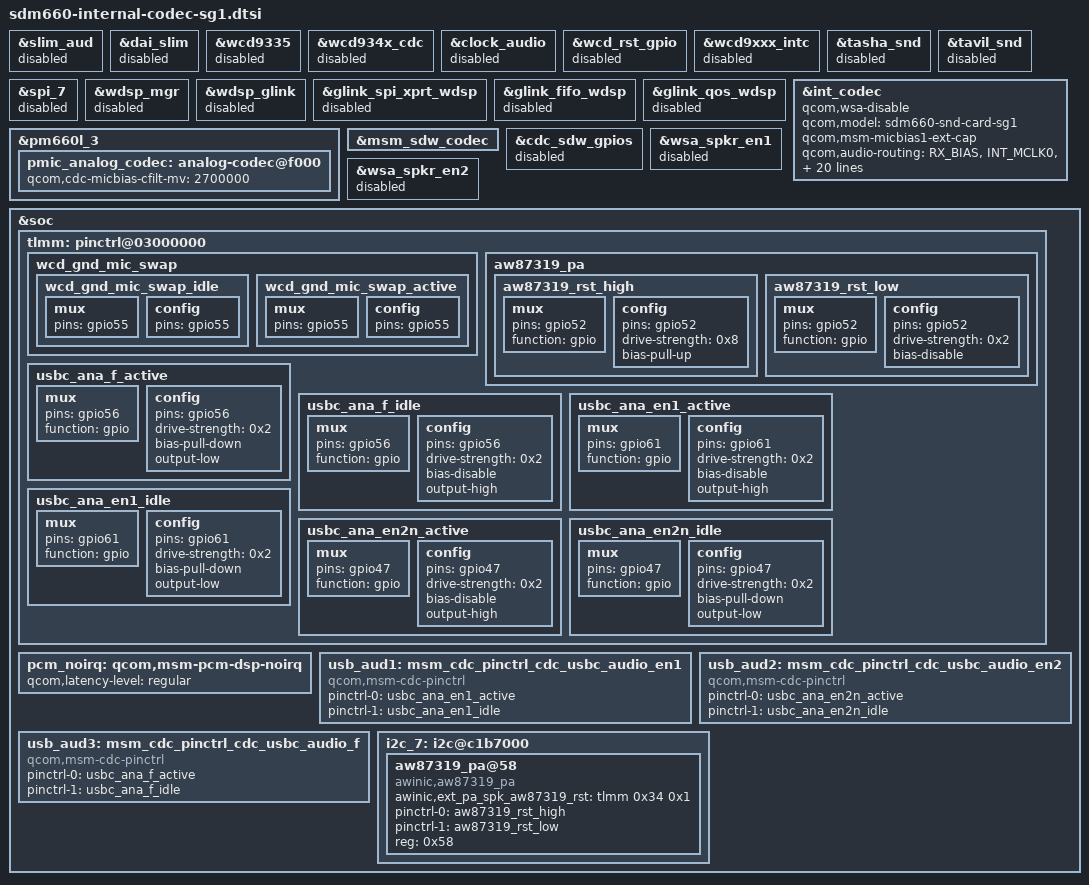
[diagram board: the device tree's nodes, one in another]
/* Copyright (c) 2017, The Linux Foundation. All rights reserved.
 *
 * This program is free software; you can redistribute it and/or modify
 * it under the terms of the GNU General Public License version 2 and
 * only version 2 as published by the Free Software Foundation.
 *
 * This program is distributed in the hope that it will be useful,
 * but WITHOUT ANY WARRANTY; without even the implied warranty of
 * MERCHANTABILITY or FITNESS FOR A PARTICULAR PURPOSE.  See the
 * GNU General Public License for more details.
 */

&slim_aud {
  status = "disabled";
};

&dai_slim {
  status = "disabled";
};

&wcd9335 {
  status = "disabled";
};

&wcd934x_cdc {
  status = "disabled";
};

&clock_audio {
  status = "disabled";
};

&wcd_rst_gpio {
  status = "disabled";
};

&wcd9xxx_intc {
  status = "disabled";
};

&tasha_snd {
  status = "disabled";
};

&tavil_snd {
  status = "disabled";
};

&spi_7 {
  status = "disabled";
};

&wdsp_mgr {
  status = "disabled";
};

&wdsp_glink {
  status = "disabled";
};

&glink_spi_xprt_wdsp {
  status = "disabled";
};

&glink_fifo_wdsp {
  status = "disabled";
};

&glink_qos_wdsp {
  status = "disabled";
};

&int_codec {
  status = "okay";
  qcom,wsa-disable;
  qcom,model = "sdm660-snd-card-sg1";
  /delete-property/ qcom,wsa-max-devs;
  /delete-property/ qcom,wsa-devs;
  /delete-property/ qcom,wsa-aux-dev-prefix;
  qcom,msm-micbias1-ext-cap;
  /delete-property/qcom,msm-micbias2-ext-cap;
  /delete-property/qcom,usbc-analog-en2_gpio;
  qcom,audio-routing = "RX_BIAS", "INT_MCLK0", "SPK_RX_BIAS", "INT_MCLK0", "INT_LDO_H", "INT_MCLK0", 
 "MIC BIAS External", "Handset Mic", "MIC BIAS External2", "Headset Mic", "MIC BIAS External",
 "Secondary Mic", "AMIC1", "MIC BIAS External", "AMIC2", "MIC BIAS External2", "AMIC3", 
 "MIC BIAS External", "DMIC1", "MIC BIAS External", "MIC BIAS External", "Digital Mic1",
 "DMIC2", "MIC BIAS External", "MIC BIAS External", "Digital Mic2", "DMIC3", "MIC BIAS External",
"MIC BIAS External", "Digital Mic3", "DMIC4", "MIC BIAS External", "MIC BIAS External", "Digital Mic4", "PDM_IN_RX1", "PDM_OUT_RX1", "PDM_IN_RX2", "PDM_OUT_RX2",
  "PDM_IN_RX3", "PDM_OUT_RX3", "ADC1_IN", "ADC1_OUT", "ADC2_IN", "ADC2_OUT", "ADC3_IN", "ADC3_OUT";
			qcom,msm-hphr-switch = <&tlmm 0x2f 0x0>;
			//qcom,msm-mbhc-usbc-audio-supported = <0x1>;

			qcom,usbc-analog-en1_gpio = <&usb_aud1>;
                       qcom,usbc-analog-en2_gpio = <&usb_aud2>;
			qcom,usbc-analog-force_detect_gpio = <&usb_aud3>;
};

&pmic_analog_codec {
  status = "okay";
};

&pm660l_3 {
	pmic_analog_codec: analog-codec@f000 {
		qcom,cdc-micbias-cfilt-mv = <2700000>;
	};
};

&msm_sdw_codec {
  status = "okay";
};


&cdc_sdw_gpios {
	status = "disabled";
};

&wsa_spkr_en1 {
	status = "disabled";
};

&wsa_spkr_en2 {
	status = "disabled";
};

&soc { 
		
         tlmm: pinctrl@03000000 {
               wcd_gnd_mic_swap {
			wcd_gnd_mic_swap_idle: wcd_gnd_mic_swap_idle {
				mux {
					pins = "gpio55";

				};
				config {
					pins = "gpio55";

				};
			};

			wcd_gnd_mic_swap_active: wcd_gnd_mic_swap_active {
				mux {
					pins = "gpio55";
				};
				config {
					pins = "gpio55";

				};
			};
		};
           };



	pcm_noirq: qcom,msm-pcm-dsp-noirq {
		qcom,latency-level = "regular";
	};
	usb_aud1: msm_cdc_pinctrl_cdc_usbc_audio_en1 {
			compatible = "qcom,msm-cdc-pinctrl";
			pinctrl-names = "aud_active", "aud_sleep";
			pinctrl-0 = <&usbc_ana_en1_active>;
			pinctrl-1 = <&usbc_ana_en1_idle>;
				};
	usb_aud2:	msm_cdc_pinctrl_cdc_usbc_audio_en2 {
			compatible = "qcom,msm-cdc-pinctrl";
			pinctrl-names = "aud_active", "aud_sleep";
			pinctrl-0 = <&usbc_ana_en2n_active>;
			pinctrl-1 = <&usbc_ana_en2n_idle>;
		};

	usb_aud3:	msm_cdc_pinctrl_cdc_usbc_audio_f {
			compatible = "qcom,msm-cdc-pinctrl";
			pinctrl-names = "aud_active", "aud_sleep";
			pinctrl-0 = <&usbc_ana_f_active>;
			pinctrl-1 = <&usbc_ana_f_idle>;

		};

/* awinic smart amp */
	i2c_7: i2c@c1b7000 {

		status = "okay";
		
		aw87319_pa@58    {
			compatible = "awinic,aw87319_pa";
                awinic,ext_pa_spk_aw87319_rst = <&tlmm 0x34 0x1>;
		pinctrl-names = "aw87319_pa_active", "aw87319_pa_off";
		pinctrl-0 = <&aw87319_rst_high>;
		pinctrl-1 = <&aw87319_rst_low>;
			reg = <0x58>;

		};
};
};

&tlmm {
	    
         aw87319_pa {
		aw87319_rst_high: aw87319_rst_high {

					mux {
						pins = "gpio52";
						function = "gpio";
					};

					config {
						pins = "gpio52";
						drive-strength = <0x8>;
						bias-pull-up;
					};
				};

		aw87319_rst_low: aw87319_rst_low {

					mux {
						pins = "gpio52";
						function = "gpio";
					};

					config {
						pins = "gpio52";
						drive-strength = <0x2>;
						bias-disable;
					};
				};
		
    };

	usbc_ana_f_active: usbc_ana_f_active {


				mux {
					pins = "gpio56";
					function = "gpio";
				};

				config {
					pins = "gpio56";
					drive-strength = <0x2>;
					bias-pull-down;
					output-low;
				};
			};

	usbc_ana_f_idle:  usbc_ana_f_idle {

				mux {
					pins = "gpio56";
					function = "gpio";
				};

				config {
					pins = "gpio56";
					drive-strength = <0x2>;
					bias-disable;
					output-high;
				};
			};

	usbc_ana_en1_active: usbc_ana_en1_active {


				mux {
					pins = "gpio61";
					function = "gpio";
				};

				config {
					pins = "gpio61";
					drive-strength = <0x2>;
					bias-disable;
					output-high;
				};
			};

	usbc_ana_en1_idle: usbc_ana_en1_idle {

				mux {
					pins = "gpio61";
					function = "gpio";
				};

				config {
					pins = "gpio61";
					drive-strength = <0x2>;
					bias-pull-down;
					output-low;
				};
			};

	usbc_ana_en2n_active: usbc_ana_en2n_active {


				mux {
					pins = "gpio47";
					function = "gpio";
				};

				config {
					pins = "gpio47";
					drive-strength = <0x2>;
					bias-disable;
					output-high;
				};
			};

	usbc_ana_en2n_idle: usbc_ana_en2n_idle {

				mux {
					pins = "gpio47";
					function = "gpio";
				};

				config {
					pins = "gpio47";
					drive-strength = <0x2>;
					bias-pull-down;
					output-low;
				};
			};
};
